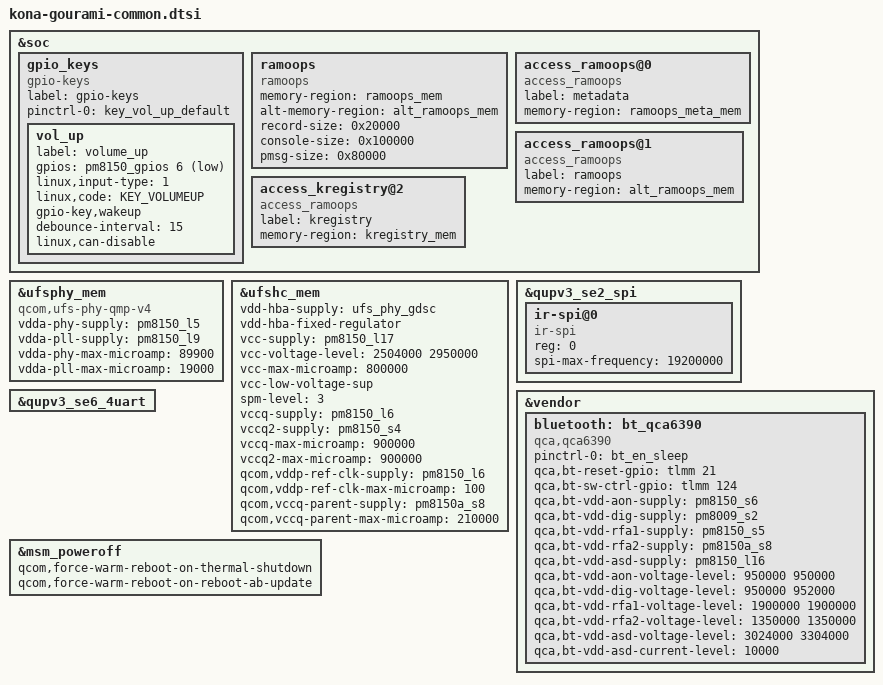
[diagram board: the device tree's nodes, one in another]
// SPDX-License-Identifier: GPL-2.0
/* Copyright (c) 2022, The Linux Foundation. All rights reserved.
 *
 * This program is free software; you can redistribute it and/or modify
 * it under the terms of the GNU General Public License version 2 and
 * only version 2 as published by the Free Software Foundation.
 *
 * This program is distributed in the hope that it will be useful,
 * but WITHOUT ANY WARRANTY; without even the implied warranty of
 * MERCHANTABILITY or FITNESS FOR A PARTICULAR PURPOSE.  See the
 * GNU General Public License for more details.
 */

#include <dt-bindings/gpio/gpio.h>
#include <dt-bindings/interrupt-controller/arm-gic.h>
#include "qcom-base/kona-pmic-overlay.dtsi"
#include "qcom-base/kona-thermal-overlay.dtsi"

#include "kona-gourami-audio.dtsi"
#include "kona-gourami-battery.dtsi"
#include "kona-gourami-camera-sensor.dtsi"
#include "kona-gourami-display.dtsi"
#include "kona-gourami-fingerprint.dtsi"
#include "kona-gourami-haptics.dtsi"
#include "kona-gourami-memory.dtsi"
#include "kona-gourami-nfc.dtsi"
#include "kona-gourami-pcie.dtsi"
#include "kona-gourami-pinctrl.dtsi"
#include "kona-gourami-qup.dtsi"
#include "kona-gourami-regulators.dtsi"
#include "kona-gourami-thermal.dtsi"
#include "kona-gourami-usb.dtsi"

&soc {
	gpio_keys {
		compatible = "gpio-keys";
		label = "gpio-keys";

		pinctrl-names = "default";
		pinctrl-0 = <&key_vol_up_default>;

		vol_up {
			label = "volume_up";
			gpios = <&pm8150_gpios 6 GPIO_ACTIVE_LOW>;
			linux,input-type = <1>;
			linux,code = <KEY_VOLUMEUP>;
			gpio-key,wakeup;
			debounce-interval = <15>;
			linux,can-disable;
		};
	};

	ramoops {
		compatible = "ramoops";
		memory-region = <&ramoops_mem>;
		alt-memory-region = <&alt_ramoops_mem>;
		record-size = <0x20000>;
		console-size = <0x100000>;
		pmsg-size = <0x80000>;
	};

	access_ramoops@0 {
		compatible = "access_ramoops";
		label = "metadata";
		memory-region = <&ramoops_meta_mem>;
	};

	access_ramoops@1 {
		compatible = "access_ramoops";
		label = "ramoops";
		memory-region = <&alt_ramoops_mem>;
	};

	access_kregistry@2 {
		compatible = "access_ramoops";
		label = "kregistry";
		memory-region = <&kregistry_mem>;
	};
};

&ufsphy_mem {
	compatible = "qcom,ufs-phy-qmp-v4";

	vdda-phy-supply = <&pm8150_l5>;
	vdda-pll-supply = <&pm8150_l9>;
	vdda-phy-max-microamp = <89900>;
	vdda-pll-max-microamp = <19000>;

	status = "ok";
};

&ufshc_mem {
	vdd-hba-supply = <&ufs_phy_gdsc>;
	vdd-hba-fixed-regulator;

	vcc-supply = <&pm8150_l17>;
	vcc-voltage-level = <2504000 2950000>;
	vcc-max-microamp = <800000>;
	vcc-low-voltage-sup;
	spm-level = <3>;

	vccq-supply = <&pm8150_l6>;
	vccq2-supply = <&pm8150_s4>;
	vccq-max-microamp = <900000>;
	vccq2-max-microamp = <900000>;

	qcom,vddp-ref-clk-supply = <&pm8150_l6>;
	qcom,vddp-ref-clk-max-microamp = <100>;

	qcom,vccq-parent-supply = <&pm8150a_s8>;
	qcom,vccq-parent-max-microamp = <210000>;

	status = "ok";
};

/* IR SPI */
&qupv3_se2_spi {
	status = "ok";
	ir-spi@0 {
		compatible = "ir-spi";
		reg = <0>;
		spi-max-frequency = <19200000>;
		status = "ok";
	};
};

/* Bluetooth */
&qupv3_se6_4uart {
	status = "ok";
};

&vendor {
	bluetooth: bt_qca6390 {
		compatible = "qca,qca6390";
		pinctrl-names = "default";
		pinctrl-0 = <&bt_en_sleep>;
		qca,bt-reset-gpio = <&tlmm 21 0>; /* BT_EN */
		qca,bt-sw-ctrl-gpio = <&tlmm 124 0>; /* SW_CTRL */
		qca,bt-vdd-aon-supply = <&pm8150_s6>;
		qca,bt-vdd-dig-supply = <&pm8009_s2>;
		qca,bt-vdd-rfa1-supply = <&pm8150_s5>;
		qca,bt-vdd-rfa2-supply = <&pm8150a_s8>;
		qca,bt-vdd-asd-supply = <&pm8150_l16>;

		qca,bt-vdd-aon-voltage-level = <950000 950000>;
		qca,bt-vdd-dig-voltage-level = <950000 952000>;
		qca,bt-vdd-rfa1-voltage-level = <1900000 1900000>;
		qca,bt-vdd-rfa2-voltage-level = <1350000 1350000>;
		qca,bt-vdd-asd-voltage-level = <3024000 3304000>;

		qca,bt-vdd-asd-current-level = <10000>;
	};
};

// Force warm reboot on 'shutdown,thermal' & 'reboot-ab-update'.
&msm_poweroff {
	qcom,force-warm-reboot-on-thermal-shutdown;
	qcom,force-warm-reboot-on-reboot-ab-update;
};
